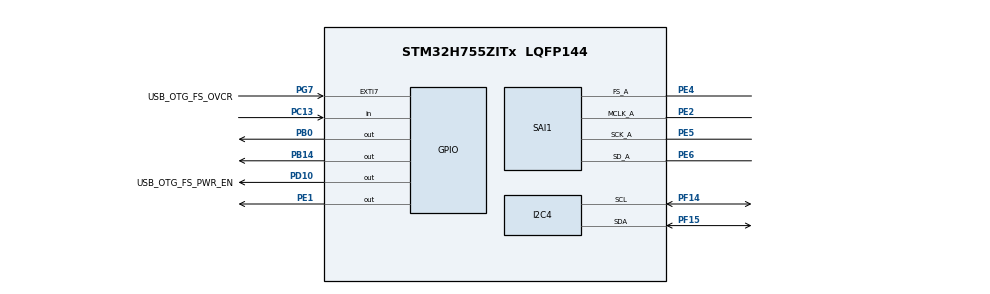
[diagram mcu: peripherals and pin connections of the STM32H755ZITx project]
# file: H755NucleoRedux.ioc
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CortexM4.IPs=FATFS_M4\:I,FREERTOS_M4\:I,IWDG2\:I,RCC,WWDG2\:I,DMA,BDMA,MDMA,NVIC2\:I,ETH,USART3,DEBUG,PDM2PCM_M4\:I,PWR,RESMGR_UTILITY,SYS_M4\:I,USB_DEVICE_M4\:I,USB_HOST_M4\:I,CORTEX_M4\:I,GPIO,OPENAMP_M4\:I,VREFBUF,NUCLEO-H755ZI-Q
CortexM7.IPs=FATFS_M7\:I,FREERTOS_M7\:I,IWDG1\:I,RCC\:I,WWDG1\:I,DMA\:I,BDMA\:I,MDMA\:I,NVIC1\:I,ETH\:I,USART3\:I,USB_OTG_FS\:I,SYS\:I,CORTEX_M7\:I,DEBUG\:I,PDM2PCM_M7\:I,PWR\:I,RESMGR_UTILITY\:I,USB_DEVICE_M7\:I,USB_HOST_M7\:I,GPIO\:I,OPENAMP_M7\:I,VREFBUF\:I,NUCLEO-H755ZI-Q\:I,MEMORYMAP\:I,I2C4\:I,SAI1\:I
Dma.Request0=SAI1_A
Dma.SAI1_A.0.Direction=DMA_MEMORY_TO_PERIPH
Dma.SAI1_A.0.EventEnable=DISABLE
Dma.SAI1_A.0.FIFOMode=DMA_FIFOMODE_DISABLE
Dma.SAI1_A.0.Instance=DMA1_Stream0
Dma.SAI1_A.0.MemDataAlignment=DMA_MDATAALIGN_WORD
Dma.SAI1_A.0.MemInc=DMA_MINC_ENABLE
Dma.SAI1_A.0.Mode=DMA_CIRCULAR
Dma.SAI1_A.0.PeriphDataAlignment=DMA_PDATAALIGN_WORD
Dma.SAI1_A.0.PeriphInc=DMA_PINC_DISABLE
Dma.SAI1_A.0.Polarity=HAL_DMAMUX_REQ_GEN_RISING
Dma.SAI1_A.0.Priority=DMA_PRIORITY_LOW
Dma.SAI1_A.0.RequestNumber=1
Dma.SAI1_A.0.SignalID=NONE
Dma.SAI1_A.0.SyncEnable=DISABLE
Dma.SAI1_A.0.SyncPolarity=HAL_DMAMUX_SYNC_NO_EVENT
Dma.SAI1_A.0.SyncRequestNumber=1
Dma.SAI1_A.0.SyncSignalID=NONE
I2C4.Speed=10
I2C4.Timing=0x6010C7FF
Mcu.Family=STM32H7
Mcu.Name=STM32H755ZITx
Mcu.Package=LQFP144
NUCLEO-H755ZI-Q.BUTTON=1
NUCLEO-H755ZI-Q.LD1=true
NUCLEO-H755ZI-Q.LD2=true
NUCLEO-H755ZI-Q.LD3=true
NUCLEO-H755ZI-Q.VCP=true
NVIC1.DMA1_Stream0_IRQn=true\:0\:0\:false\:false\:true\:false\:true\:true
NVIC1.EXTI15_10_IRQn=true\:0\:0\:false\:false\:true\:false\:true\:true
NVIC1.PriorityGroup=NVIC_PRIORITYGROUP_4
NVIC2.PriorityGroup=NVIC_PRIORITYGROUP_4
PA1.PinAttribute=CortexM7
PA1.Signal=ETH_REF_CLK
PA11.PinAttribute=CortexM7
PA11.Signal=USB_OTG_FS_DM
PA12.PinAttribute=CortexM7
PA12.Signal=USB_OTG_FS_DP
PA2.PinAttribute=CortexM7
PA2.Signal=ETH_MDIO
PA7.PinAttribute=CortexM7
PA7.Signal=ETH_CRS_DV
PA8.PinAttribute=CortexM7
PA8.Signal=USB_OTG_FS_SOF
PA9.PinAttribute=CortexM7
PA9.Signal=USB_OTG_FS_VBUS
PB0.Signal=GPIO_Output
PB13.PinAttribute=CortexM7
PB13.Signal=ETH_TXD1
PB14.Signal=GPIO_Output
PC1.PinAttribute=CortexM7
PC1.Signal=ETH_MDC
PC13.Signal=GPIO_Input
PC14-OSC32_IN\ (OSC32_IN).PinAttribute=Free
PC14-OSC32_IN\ (OSC32_IN).Signal=RCC_OSC32_IN
PC15-OSC32_OUT\ (OSC32_OUT).PinAttribute=Free
PC15-OSC32_OUT\ (OSC32_OUT).Signal=RCC_OSC32_OUT
PC4.PinAttribute=CortexM7
PC4.Signal=ETH_RXD0
PC5.PinAttribute=CortexM7
PC5.Signal=ETH_RXD1
PD10.GPIO_Label=USB_OTG_FS_PWR_EN
PD10.PinAttribute=Free
PD10.Signal=GPIO_Output
PD8.Signal=USART3_TX
PD9.Signal=USART3_RX
PE1.Signal=GPIO_Output
PE2.Mode=SAI_A_MasterWithClock
PE2.PinAttribute=CortexM7
PE2.Signal=SAI1_MCLK_A
PE4.Mode=SAI_A_MasterWithClock
PE4.PinAttribute=CortexM7
PE4.Signal=SAI1_FS_A
PE5.Mode=SAI_A_MasterWithClock
PE5.PinAttribute=CortexM7
PE5.Signal=SAI1_SCK_A
PE6.Mode=SAI_A_MasterWithClock
PE6.PinAttribute=CortexM7
PE6.Signal=SAI1_SD_A
PF14.GPIO_Mode=GPIO_MODE_AF_OD
PF14.GPIO_Pu=GPIO_PULLUP
PF14.GPIO_Speed=GPIO_SPEED_FREQ_HIGH
PF14.Mode=I2C
PF14.PinAttribute=CortexM7
PF14.Signal=I2C4_SCL
PF15.GPIO_Mode=GPIO_MODE_AF_OD
PF15.GPIO_Pu=GPIO_PULLUP
PF15.GPIO_Speed=GPIO_SPEED_FREQ_HIGH
PF15.Mode=I2C
PF15.PinAttribute=CortexM7
PF15.Signal=I2C4_SDA
PG11.PinAttribute=CortexM7
PG11.Signal=ETH_TX_EN
PG13.PinAttribute=CortexM7
PG13.Signal=ETH_TXD0
PG7.GPIO_Label=USB_OTG_FS_OVCR
PG7.PinAttribute=Free
PG7.Signal=GPXTI7
PH0-OSC_IN\ (PH0).PinAttribute=Free
PH0-OSC_IN\ (PH0).Signal=RCC_OSC_IN
PH1-OSC_OUT\ (PH1).PinAttribute=Free
PH1-OSC_OUT\ (PH1).Signal=RCC_OSC_OUT
ProjectManager.HeapSize=M4-0x200,M7-0x200
ProjectManager.StackSize=M4-0x400,M7-0x400
ProjectManager.TargetToolchain=STM32CubeIDE
RCC.ADCFreq_Value=129000000
RCC.APB1Freq_Value=64000000
RCC.APB2Freq_Value=64000000
RCC.APB3Freq_Value=64000000
RCC.APB4Freq_Value=64000000
RCC.CortexFreq_Value=64000000
RCC.DIVM1=5
RCC.DIVN1=48
RCC.DIVN3=128
RCC.DIVQ1=50
RCC.DIVR3=8
RCC.HCLKFreq_Value=64000000
RCC.I2C4CLockSelection=RCC_I2C4CLKSOURCE_PLL3
RCC.PLL2FRACN=0
RCC.PLL3FRACN=0
RCC.PLLFRACN=0
RCC.SYSCLKFreq_VALUE=64000000
RCC.SupplySource=PWR_DIRECT_SMPS_SUPPLY
RCC.USBFreq_Value=12288000
SAI1.AudioFrequency-SAI_A_MasterWithClock=SAI_AUDIO_FREQUENCY_48K
SAI1.ErrorAudioFreq-SAI_A_MasterWithClock=0.0 %
SAI1.Instance-SAI_A_MasterWithClock=SAI$Index_Block_A
SAI1.MClockEnable-SAI_A_MasterWithClock=SAI_MASTERCLOCK_ENABLE
SAI1.OutputDrive-SAI_A_MasterWithClock=SAI_OUTPUTDRIVE_DISABLE
SAI1.RealAudioFreq-SAI_A_MasterWithClock=48.0 KHz
SAI1.VirtualMode-SAI_A_MasterWithClock=VM_MASTER
VP_MEMORYMAP_VS_MEMORYMAP.Mode=CurAppReg
VP_NUCLEO-H755ZI-Q_VS_BSP_COMMON.Mode=COMMON
VP_SYS_M4_VS_Systick.Mode=SysTick
board=NUCLEO-H755ZI-Q

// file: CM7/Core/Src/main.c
/* USER CODE BEGIN Header */
/**
  ******************************************************************************
  * @file           : main.c
  * @brief          : Main program body
  ******************************************************************************
  * @attention
  *
  * Copyright (c) 2025 STMicroelectronics.
  * All rights reserved.
  *
  * This software is licensed under terms that can be found in the LICENSE file
  * in the root directory of this software component.
  * If no LICENSE file comes with this software, it is provided AS-IS.
  *
  ******************************************************************************
  */
/* USER CODE END Header */
#include "main.h"
#include "stdio.h"

/* USER CODE BEGIN PD */

#ifndef HSEM_ID_0
#define HSEM_ID_0 (0U) /* HW semaphore 0*/
#endif

/* USER CODE END PD */

COM_InitTypeDef BspCOMInit;

I2C_HandleTypeDef hi2c4;

SAI_HandleTypeDef hsai_BlockA1;
DMA_HandleTypeDef hdma_sai1_a;

void SystemClock_Config(void);
static void MX_GPIO_Init(void);
static void MX_DMA_Init(void);
static void MX_I2C4_Init(void);
static void MX_SAI1_Init(void);

int _write(int le, char *ptr, int len)
    {
    int DataIdx;
    for(DataIdx = 0; DataIdx < len; DataIdx++)
        {
        ITM_SendChar(*ptr++);
        }
    return len;
    }

void I2C_Scan(I2C_HandleTypeDef *hi2c)
{
    char msg[64];
    HAL_StatusTypeDef res;
    // I2C addresses are 7-bit. The HAL function expects the 7-bit address shifted left by 1.
    for (uint8_t addr = 1; addr < 128; addr++) {
        // Try up to 3 times with a small timeout.
        res = HAL_I2C_IsDeviceReady(hi2c, addr << 1, 3, 10);
        if (res == HAL_OK) {
            sprintf(msg, "Device found at 0x%02X\r\n", addr);
            // You can send this message over UART, SWV, or your debugger console.
            printf("%s", msg);
        }
    }
}
int main(void)
{

/* USER CODE BEGIN Boot_Mode_Sequence_0 */
  int32_t timeout;
/* USER CODE END Boot_Mode_Sequence_0 */

/* USER CODE BEGIN Boot_Mode_Sequence_1 */
  /* Wait until CPU2 boots and enters in stop mode or timeout*/
  timeout = 0xFFFF;
//  while((__HAL_RCC_GET_FLAG(RCC_FLAG_D2CKRDY) != RESET) && (timeout-- > 0));
//  if ( timeout < 0 )
//  {
//  Error_Handler();
//  }
/* USER CODE END Boot_Mode_Sequence_1 */
  /* MCU Configuration--------------------------------------------------------*/

  /* Reset of all peripherals, Initializes the Flash interface and the Systick. */
  HAL_Init();

  /* Configure the system clock */
  SystemClock_Config();
/* USER CODE BEGIN Boot_Mode_Sequence_2 */
/* When system initialization is finished, Cortex-M7 will release Cortex-M4 by means of
HSEM notification */
/*HW semaphore Clock enable*/
__HAL_RCC_HSEM_CLK_ENABLE();
/*Take HSEM */
HAL_HSEM_FastTake(HSEM_ID_0);
/*Release HSEM in order to notify the CPU2(CM4)*/
HAL_HSEM_Release(HSEM_ID_0,0);
/* wait until CPU2 wakes up from stop mode */
timeout = 0xFFFF;
while((__HAL_RCC_GET_FLAG(RCC_FLAG_D2CKRDY) == RESET) && (timeout-- > 0));
if ( timeout < 0 )
{
Error_Handler();
}
/* USER CODE END Boot_Mode_Sequence_2 */

  /* Initialize all configured peripherals */
  MX_GPIO_Init();
  MX_DMA_Init();
  MX_I2C4_Init();
  MX_SAI1_Init();

  /* Initialize leds */
  BSP_LED_Init(LED_GREEN);
  BSP_LED_Init(LED_YELLOW);
  BSP_LED_Init(LED_RED);

  /* Initialize USER push-button, will be used to trigger an interrupt each time it's pressed.*/
  BSP_PB_Init(BUTTON_USER, BUTTON_MODE_EXTI);

  /* Initialize COM1 port (115200, 8 bits (7-bit data + 1 stop bit), no parity */
  BspCOMInit.BaudRate   = 115200;
  BspCOMInit.WordLength = COM_WORDLENGTH_8B;
  BspCOMInit.StopBits   = COM_STOPBITS_1;
  BspCOMInit.Parity     = COM_PARITY_NONE;
  BspCOMInit.HwFlowCtl  = COM_HWCONTROL_NONE;
  if (BSP_COM_Init(COM1, &BspCOMInit) != BSP_ERROR_NONE)
  {
    Error_Handler();
  }

  /* Infinite loop */
  /* USER CODE BEGIN WHILE */

  uint16_t audioBuf[256];
  memset(audioBuf, 0, sizeof(audioBuf)); // e.g. silence

//  if (HAL_SAI_Transmit_DMA(&hsai_BlockA1, (uint8_t*)audioBuf, 256) != HAL_OK)
//      {
//          Error_Handler();
//      }

//  uint8_t dummyData[2] = {0x00, 0x00}; // or however large you like
//
//
//  if (HAL_SAI_Transmit(&hsai_BlockA1, dummyData, sizeof(dummyData), 100) != HAL_OK)
//  {
//      Error_Handler();
//  }

  printf("starting program\r");

  HAL_StatusTypeDef status;
  uint8_t pData = 0x05;
  uint8_t registerNum = 0x00;
  status = HAL_I2C_Mem_Read(&hi2c4, (0x4A << 1), 0x00,
          I2C_MEMADD_SIZE_8BIT, &pData, 1, 100);

  I2C_Scan(&hi2c4);

  while (1)
  {

    /* USER CODE END WHILE */
	  status = HAL_I2C_Mem_Read(&hi2c4, 0x4A, 0x00,
	            I2C_MEMADD_SIZE_8BIT, &pData, 1, 100);

  }
}

void SystemClock_Config(void)
{
  RCC_OscInitTypeDef RCC_OscInitStruct = {0};
  RCC_ClkInitTypeDef RCC_ClkInitStruct = {0};

  /** Supply configuration update enable
  */
  HAL_PWREx_ConfigSupply(PWR_DIRECT_SMPS_SUPPLY);

  /** Configure the main internal regulator output voltage
  */
  __HAL_PWR_VOLTAGESCALING_CONFIG(PWR_REGULATOR_VOLTAGE_SCALE3);

  while(!__HAL_PWR_GET_FLAG(PWR_FLAG_VOSRDY)) {}

  /** Initializes the RCC Oscillators according to the specified parameters
  * in the RCC_OscInitTypeDef structure.
  */
  RCC_OscInitStruct.OscillatorType = RCC_OSCILLATORTYPE_HSI;
  RCC_OscInitStruct.HSIState = RCC_HSI_DIV1;
  RCC_OscInitStruct.HSICalibrationValue = RCC_HSICALIBRATION_DEFAULT;
  RCC_OscInitStruct.PLL.PLLState = RCC_PLL_ON;
  RCC_OscInitStruct.PLL.PLLSource = RCC_PLLSOURCE_HSI;
  RCC_OscInitStruct.PLL.PLLM = 5;
  RCC_OscInitStruct.PLL.PLLN = 48;
  RCC_OscInitStruct.PLL.PLLP = 2;
  RCC_OscInitStruct.PLL.PLLQ = 50;
  RCC_OscInitStruct.PLL.PLLR = 2;
  RCC_OscInitStruct.PLL.PLLRGE = RCC_PLL1VCIRANGE_3;
  RCC_OscInitStruct.PLL.PLLVCOSEL = RCC_PLL1VCOWIDE;
  RCC_OscInitStruct.PLL.PLLFRACN = 0;
  if (HAL_RCC_OscConfig(&RCC_OscInitStruct) != HAL_OK)
  {
    Error_Handler();
  }

  /** Initializes the CPU, AHB and APB buses clocks
  */
  RCC_ClkInitStruct.ClockType = RCC_CLOCKTYPE_HCLK|RCC_CLOCKTYPE_SYSCLK
                              |RCC_CLOCKTYPE_PCLK1|RCC_CLOCKTYPE_PCLK2
                              |RCC_CLOCKTYPE_D3PCLK1|RCC_CLOCKTYPE_D1PCLK1;
  RCC_ClkInitStruct.SYSCLKSource = RCC_SYSCLKSOURCE_HSI;
  RCC_ClkInitStruct.SYSCLKDivider = RCC_SYSCLK_DIV1;
  RCC_ClkInitStruct.AHBCLKDivider = RCC_HCLK_DIV1;
  RCC_ClkInitStruct.APB3CLKDivider = RCC_APB3_DIV1;
  RCC_ClkInitStruct.APB1CLKDivider = RCC_APB1_DIV1;
  RCC_ClkInitStruct.APB2CLKDivider = RCC_APB2_DIV1;
  RCC_ClkInitStruct.APB4CLKDivider = RCC_APB4_DIV1;

  if (HAL_RCC_ClockConfig(&RCC_ClkInitStruct, FLASH_LATENCY_1) != HAL_OK)
  {
    Error_Handler();
  }
}

static void MX_I2C4_Init(void)
{

  hi2c4.Instance = I2C4;
  hi2c4.Init.Timing = 0x6010C7FF;
  hi2c4.Init.OwnAddress1 = 0;
  hi2c4.Init.AddressingMode = I2C_ADDRESSINGMODE_7BIT;
  hi2c4.Init.DualAddressMode = I2C_DUALADDRESS_DISABLE;
  hi2c4.Init.OwnAddress2 = 0;
  hi2c4.Init.OwnAddress2Masks = I2C_OA2_NOMASK;
  hi2c4.Init.GeneralCallMode = I2C_GENERALCALL_DISABLE;
  hi2c4.Init.NoStretchMode = I2C_NOSTRETCH_DISABLE;
  if (HAL_I2C_Init(&hi2c4) != HAL_OK)
  {
    Error_Handler();
  }

  /** Configure Analogue filter
  */
  if (HAL_I2CEx_ConfigAnalogFilter(&hi2c4, I2C_ANALOGFILTER_ENABLE) != HAL_OK)
  {
    Error_Handler();
  }

  /** Configure Digital filter
  */
  if (HAL_I2CEx_ConfigDigitalFilter(&hi2c4, 0) != HAL_OK)
  {
    Error_Handler();
  }

}

static void MX_SAI1_Init(void)
{

  hsai_BlockA1.Instance = SAI1_Block_A;
  hsai_BlockA1.Init.Protocol = SAI_FREE_PROTOCOL;
  hsai_BlockA1.Init.AudioMode = SAI_MODEMASTER_TX;
  hsai_BlockA1.Init.DataSize = SAI_DATASIZE_8;
  hsai_BlockA1.Init.FirstBit = SAI_FIRSTBIT_MSB;
  hsai_BlockA1.Init.ClockStrobing = SAI_CLOCKSTROBING_FALLINGEDGE;
  hsai_BlockA1.Init.Synchro = SAI_ASYNCHRONOUS;
  hsai_BlockA1.Init.OutputDrive = SAI_OUTPUTDRIVE_DISABLE;
  hsai_BlockA1.Init.NoDivider = SAI_MASTERDIVIDER_ENABLE;
  hsai_BlockA1.Init.FIFOThreshold = SAI_FIFOTHRESHOLD_EMPTY;
  hsai_BlockA1.Init.AudioFrequency = SAI_AUDIO_FREQUENCY_48K;
  hsai_BlockA1.Init.SynchroExt = SAI_SYNCEXT_DISABLE;
  hsai_BlockA1.Init.MonoStereoMode = SAI_STEREOMODE;
  hsai_BlockA1.Init.CompandingMode = SAI_NOCOMPANDING;
  hsai_BlockA1.Init.TriState = SAI_OUTPUT_NOTRELEASED;
  hsai_BlockA1.Init.PdmInit.Activation = DISABLE;
  hsai_BlockA1.Init.PdmInit.MicPairsNbr = 1;
  hsai_BlockA1.Init.PdmInit.ClockEnable = SAI_PDM_CLOCK1_ENABLE;
  hsai_BlockA1.FrameInit.FrameLength = 8;
  hsai_BlockA1.FrameInit.ActiveFrameLength = 1;
  hsai_BlockA1.FrameInit.FSDefinition = SAI_FS_STARTFRAME;
  hsai_BlockA1.FrameInit.FSPolarity = SAI_FS_ACTIVE_LOW;
  hsai_BlockA1.FrameInit.FSOffset = SAI_FS_FIRSTBIT;
  hsai_BlockA1.SlotInit.FirstBitOffset = 0;
  hsai_BlockA1.SlotInit.SlotSize = SAI_SLOTSIZE_DATASIZE;
  hsai_BlockA1.SlotInit.SlotNumber = 1;
  hsai_BlockA1.SlotInit.SlotActive = 0x00000000;
  if (HAL_SAI_Init(&hsai_BlockA1) != HAL_OK)
  {
    Error_Handler();
  }

}

static void MX_DMA_Init(void)
{

  /* DMA controller clock enable */
  __HAL_RCC_DMA1_CLK_ENABLE();

  /* DMA interrupt init */
  /* DMA1_Stream0_IRQn interrupt configuration */
  HAL_NVIC_SetPriority(DMA1_Stream0_IRQn, 0, 0);
  HAL_NVIC_EnableIRQ(DMA1_Stream0_IRQn);

}

static void MX_GPIO_Init(void)
{
  GPIO_InitTypeDef GPIO_InitStruct = {0};

  /* GPIO Ports Clock Enable */
  __HAL_RCC_GPIOE_CLK_ENABLE();
  __HAL_RCC_GPIOC_CLK_ENABLE();
  __HAL_RCC_GPIOA_CLK_ENABLE();
  __HAL_RCC_GPIOF_CLK_ENABLE();
  __HAL_RCC_GPIOB_CLK_ENABLE();
  __HAL_RCC_GPIOG_CLK_ENABLE();

  /*Configure GPIO pins : PC1 PC4 PC5 */
  GPIO_InitStruct.Pin = GPIO_PIN_1|GPIO_PIN_4|GPIO_PIN_5;
  GPIO_InitStruct.Mode = GPIO_MODE_AF_PP;
  GPIO_InitStruct.Pull = GPIO_NOPULL;
  GPIO_InitStruct.Speed = GPIO_SPEED_FREQ_LOW;
  GPIO_InitStruct.Alternate = GPIO_AF11_ETH;
  HAL_GPIO_Init(GPIOC, &GPIO_InitStruct);

  /*Configure GPIO pins : PA1 PA2 PA7 */
  GPIO_InitStruct.Pin = GPIO_PIN_1|GPIO_PIN_2|GPIO_PIN_7;
  GPIO_InitStruct.Mode = GPIO_MODE_AF_PP;
  GPIO_InitStruct.Pull = GPIO_NOPULL;
  GPIO_InitStruct.Speed = GPIO_SPEED_FREQ_LOW;
  GPIO_InitStruct.Alternate = GPIO_AF11_ETH;
  HAL_GPIO_Init(GPIOA, &GPIO_InitStruct);

  /*Configure GPIO pin : PB13 */
  GPIO_InitStruct.Pin = GPIO_PIN_13;
  GPIO_InitStruct.Mode = GPIO_MODE_AF_PP;
  GPIO_InitStruct.Pull = GPIO_NOPULL;
  GPIO_InitStruct.Speed = GPIO_SPEED_FREQ_LOW;
  GPIO_InitStruct.Alternate = GPIO_AF11_ETH;
  HAL_GPIO_Init(GPIOB, &GPIO_InitStruct);

  /*Configure GPIO pins : PA8 PA11 PA12 */
  GPIO_InitStruct.Pin = GPIO_PIN_8|GPIO_PIN_11|GPIO_PIN_12;
  GPIO_InitStruct.Mode = GPIO_MODE_AF_PP;
  GPIO_InitStruct.Pull = GPIO_NOPULL;
  GPIO_InitStruct.Speed = GPIO_SPEED_FREQ_LOW;
  GPIO_InitStruct.Alternate = GPIO_AF10_OTG1_FS;
  HAL_GPIO_Init(GPIOA, &GPIO_InitStruct);

  /*Configure GPIO pins : PG11 PG13 */
  GPIO_InitStruct.Pin = GPIO_PIN_11|GPIO_PIN_13;
  GPIO_InitStruct.Mode = GPIO_MODE_AF_PP;
  GPIO_InitStruct.Pull = GPIO_NOPULL;
  GPIO_InitStruct.Speed = GPIO_SPEED_FREQ_LOW;
  GPIO_InitStruct.Alternate = GPIO_AF11_ETH;
  HAL_GPIO_Init(GPIOG, &GPIO_InitStruct);

}

void Error_Handler(void)
{
  __disable_irq();
  while (1)
  {
  }
}
